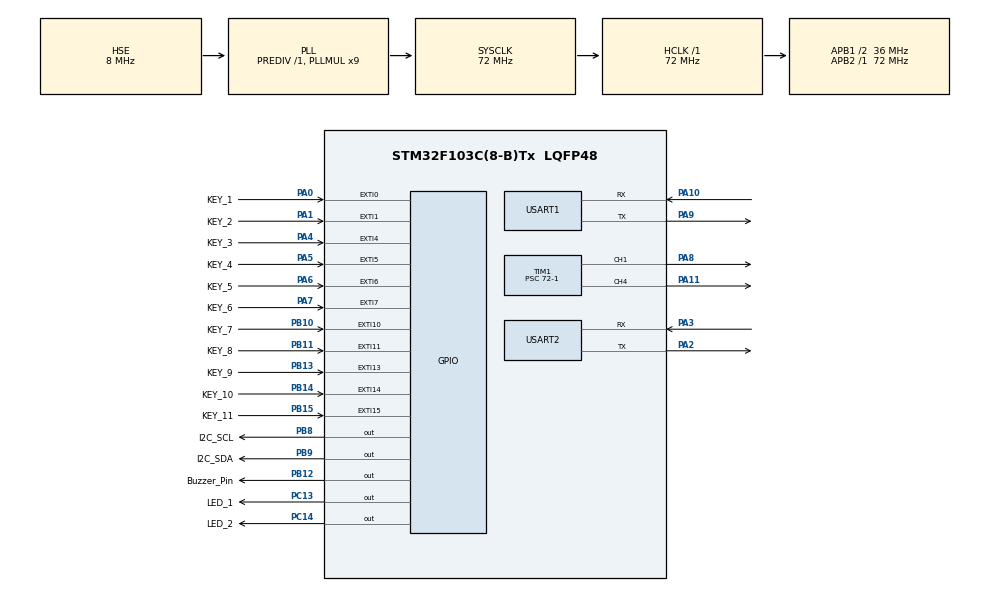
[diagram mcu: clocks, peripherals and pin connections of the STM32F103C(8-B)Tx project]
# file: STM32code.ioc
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Mcu.Family=STM32F1
Mcu.Name=STM32F103C(8-B)Tx
Mcu.Package=LQFP48
NVIC.EXTI0_IRQn=true\:1\:0\:true\:false\:true\:true\:true\:true
NVIC.EXTI15_10_IRQn=true\:1\:0\:true\:false\:true\:true\:true\:true
NVIC.EXTI1_IRQn=true\:1\:0\:true\:false\:true\:true\:true\:true
NVIC.EXTI4_IRQn=true\:1\:0\:true\:false\:true\:true\:true\:true
NVIC.EXTI9_5_IRQn=true\:1\:0\:true\:false\:true\:true\:true\:true
NVIC.PriorityGroup=NVIC_PRIORITYGROUP_4
NVIC.TIM4_IRQn=true\:0\:0\:false\:false\:true\:true\:true\:true
NVIC.USART1_IRQn=true\:0\:0\:false\:false\:true\:true\:true\:true
NVIC.USART2_IRQn=true\:0\:0\:false\:false\:true\:true\:true\:true
PA0-WKUP.GPIO_Label=KEY_1
PA0-WKUP.GPIO_PuPd=GPIO_PULLDOWN
PA0-WKUP.Signal=GPXTI0
PA1.GPIO_Label=KEY_2
PA1.GPIO_PuPd=GPIO_PULLDOWN
PA1.Signal=GPXTI1
PA10.Mode=Asynchronous
PA10.Signal=USART1_RX
PA11.Signal=S_TIM1_CH4
PA13.Mode=Serial_Wire
PA13.Signal=SYS_JTMS-SWDIO
PA14.Mode=Serial_Wire
PA14.Signal=SYS_JTCK-SWCLK
PA2.Mode=Asynchronous
PA2.Signal=USART2_TX
PA3.Mode=Asynchronous
PA3.Signal=USART2_RX
PA4.GPIO_Label=KEY_3
PA4.GPIO_PuPd=GPIO_PULLDOWN
PA4.Signal=GPXTI4
PA5.GPIO_Label=KEY_4
PA5.GPIO_PuPd=GPIO_PULLDOWN
PA5.Signal=GPXTI5
PA6.GPIO_Label=KEY_5
PA6.GPIO_PuPd=GPIO_PULLDOWN
PA6.Signal=GPXTI6
PA7.GPIO_Label=KEY_6
PA7.GPIO_PuPd=GPIO_PULLDOWN
PA7.Signal=GPXTI7
PA8.Signal=S_TIM1_CH1
PA9.Mode=Asynchronous
PA9.Signal=USART1_TX
PB10.GPIO_Label=KEY_7
PB10.GPIO_PuPd=GPIO_PULLDOWN
PB10.Signal=GPXTI10
PB11.GPIO_Label=KEY_8
PB11.GPIO_PuPd=GPIO_PULLDOWN
PB11.Signal=GPXTI11
PB12.GPIO_Label=Buzzer_Pin
PB12.GPIO_PuPd=GPIO_PULLDOWN
PB12.GPIO_Speed=GPIO_SPEED_FREQ_MEDIUM
PB12.PinState=GPIO_PIN_RESET
PB12.Signal=GPIO_Output
PB13.GPIO_Label=KEY_9
PB13.GPIO_PuPd=GPIO_PULLDOWN
PB13.Signal=GPXTI13
PB14.GPIO_Label=KEY_10
PB14.GPIO_PuPd=GPIO_PULLDOWN
PB14.Signal=GPXTI14
PB15.GPIO_Label=KEY_11
PB15.GPIO_PuPd=GPIO_PULLDOWN
PB15.Signal=GPXTI15
PB8.GPIO_Label=I2C_SCL
PB8.GPIO_ModeDefaultOutputPP=GPIO_MODE_OUTPUT_OD
PB8.GPIO_PuPd=GPIO_PULLUP
PB8.GPIO_Speed=GPIO_SPEED_FREQ_HIGH
PB8.Signal=GPIO_Output
PB9.GPIO_Label=I2C_SDA
PB9.GPIO_ModeDefaultOutputPP=GPIO_MODE_OUTPUT_OD
PB9.GPIO_PuPd=GPIO_PULLUP
PB9.GPIO_Speed=GPIO_SPEED_FREQ_HIGH
PB9.Signal=GPIO_Output
PC13-TAMPER-RTC.GPIO_Label=LED_1
PC13-TAMPER-RTC.Signal=GPIO_Output
PC14-OSC32_IN.GPIO_Label=LED_2
PC14-OSC32_IN.Signal=GPIO_Output
PD0-OSC_IN.Mode=HSE-External-Oscillator
PD0-OSC_IN.Signal=RCC_OSC_IN
PD1-OSC_OUT.Mode=HSE-External-Oscillator
PD1-OSC_OUT.Signal=RCC_OSC_OUT
ProjectManager.HeapSize=0x200
ProjectManager.StackSize=0x400
ProjectManager.TargetToolchain=MDK-ARM V5.32
RCC.AHBFreq_Value=72000000
RCC.APB1CLKDivider=RCC_HCLK_DIV2
RCC.APB1Freq_Value=36000000
RCC.APB1TimFreq_Value=72000000
RCC.APB2Freq_Value=72000000
RCC.APB2TimFreq_Value=72000000
RCC.HCLKFreq_Value=72000000
RCC.PLLMUL=RCC_PLL_MUL9
RCC.PLLSourceVirtual=RCC_PLLSOURCE_HSE
RCC.SYSCLKFreq_VALUE=72000000
RCC.SYSCLKSource=RCC_SYSCLKSOURCE_PLLCLK
RCC.USBFreq_Value=72000000
SH.S_TIM1_CH1.0=TIM1_CH1,PWM Generation1 CH1
SH.S_TIM1_CH4.0=TIM1_CH4,PWM Generation4 CH4
TIM1.AutoReloadPreload=TIM_AUTORELOAD_PRELOAD_ENABLE
TIM1.Channel-PWM\ Generation1\ CH1=TIM_CHANNEL_1
TIM1.Channel-PWM\ Generation4\ CH4=TIM_CHANNEL_4
TIM1.Period=20000-1
TIM1.Prescaler=72-1
TIM4.AutoReloadPreload=TIM_AUTORELOAD_PRELOAD_ENABLE
TIM4.Period=1000-1
TIM4.Prescaler=72-1
USART1.VirtualMode=VM_ASYNC
USART2.VirtualMode=VM_ASYNC
VP_TIM1_VS_ClockSourceINT.Mode=Internal
VP_TIM4_VS_ClockSourceINT.Mode=Internal
board=custom

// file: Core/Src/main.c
/* USER CODE BEGIN Header */
/**
  ******************************************************************************
  * @file           : main.c
  * @brief          : Main program body
  ******************************************************************************
  * @attention
  *
  * Copyright (c) 2023 STMicroelectronics.
  * All rights reserved.
  *
  * This software is licensed under terms that can be found in the LICENSE file
  * in the root directory of this software component.
  * If no LICENSE file comes with this software, it is provided AS-IS.
  *
  ******************************************************************************
  */
/* USER CODE END Header */
#include "main.h"
#include "tim.h"
#include "usart.h"
#include "gpio.h"

/* USER CODE BEGIN Includes */
#include "app.h"  //应用层头文件
/* USER CODE END Includes */

void SystemClock_Config(void);

int main(void)
{

  /* MCU Configuration--------------------------------------------------------*/

  /* Reset of all peripherals, Initializes the Flash interface and the Systick. */
  HAL_Init();

  /* Configure the system clock */
  SystemClock_Config();

  /* Initialize all configured peripherals */
  MX_GPIO_Init();
  MX_TIM1_Init();
  MX_USART1_UART_Init();
  MX_TIM4_Init();
  MX_USART2_UART_Init();
  /* USER CODE BEGIN 2 */
  App_Init();  //应用层初始化

  /* USER CODE END 2 */

  /* Infinite loop */
  while (1)
  {

    /* USER CODE BEGIN 3 */
    App_Task();  //应用层任务

  }
  /* USER CODE END 3 */
}

void SystemClock_Config(void)
{
  RCC_OscInitTypeDef RCC_OscInitStruct = {0};
  RCC_ClkInitTypeDef RCC_ClkInitStruct = {0};

  /** Initializes the RCC Oscillators according to the specified parameters
  * in the RCC_OscInitTypeDef structure.
  */
  RCC_OscInitStruct.OscillatorType = RCC_OSCILLATORTYPE_HSE;
  RCC_OscInitStruct.HSEState = RCC_HSE_ON;
  RCC_OscInitStruct.HSEPredivValue = RCC_HSE_PREDIV_DIV1;
  RCC_OscInitStruct.HSIState = RCC_HSI_ON;
  RCC_OscInitStruct.PLL.PLLState = RCC_PLL_ON;
  RCC_OscInitStruct.PLL.PLLSource = RCC_PLLSOURCE_HSE;
  RCC_OscInitStruct.PLL.PLLMUL = RCC_PLL_MUL9;
  if (HAL_RCC_OscConfig(&RCC_OscInitStruct) != HAL_OK)
  {
    Error_Handler();
  }

  /** Initializes the CPU, AHB and APB buses clocks
  */
  RCC_ClkInitStruct.ClockType = RCC_CLOCKTYPE_HCLK|RCC_CLOCKTYPE_SYSCLK
                              |RCC_CLOCKTYPE_PCLK1|RCC_CLOCKTYPE_PCLK2;
  RCC_ClkInitStruct.SYSCLKSource = RCC_SYSCLKSOURCE_PLLCLK;
  RCC_ClkInitStruct.AHBCLKDivider = RCC_SYSCLK_DIV1;
  RCC_ClkInitStruct.APB1CLKDivider = RCC_HCLK_DIV2;
  RCC_ClkInitStruct.APB2CLKDivider = RCC_HCLK_DIV1;

  if (HAL_RCC_ClockConfig(&RCC_ClkInitStruct, FLASH_LATENCY_2) != HAL_OK)
  {
    Error_Handler();
  }
}

void Error_Handler(void)
{
  __disable_irq();
  while (1)
  {
  }
}
